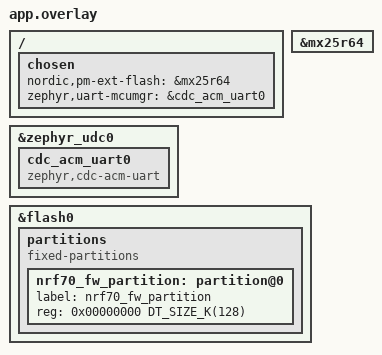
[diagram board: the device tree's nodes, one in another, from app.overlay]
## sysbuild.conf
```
# Add MCUboot
SB_CONFIG_BOOTLOADER_MCUBOOT=y

#Wifi stuff
SB_CONFIG_WIFI_NRF70=y

SB_CONFIG_MCUBOOT_UPDATEABLE_IMAGES=3

SB_CONFIG_WIFI_PATCHES_EXT_FLASH_STORE=y

SB_CONFIG_BOOTLOADER_MCUBOOT=y
SB_CONFIG_BOOT_SIGNATURE_TYPE_ECDSA_P256=y
SB_CONFIG_MCUBOOT_MODE_OVERWRITE_ONLY=y
SB_CONFIG_PM_EXTERNAL_FLASH_MCUBOOT_SECONDARY=y
SB_CONFIG_NETCORE_HCI_IPC=y
SB_CONFIG_NETCORE_APP_UPDATE=y
SB_CONFIG_SECURE_BOOT_NETCORE=y
```

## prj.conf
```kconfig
#
# Copyright (c) 2022 Nordic Semiconductor ASA
#
# SPDX-License-Identifier: LicenseRef-Nordic-5-Clause
#
# Enable MCUmgr and dependencies.

CONFIG_GPIO=y

# Enable mcumgr DFU in application
CONFIG_MCUMGR=y

# Enable MCUMGR management for both OS and Images
CONFIG_MCUMGR_GRP_OS=y
CONFIG_MCUMGR_GRP_IMG=y

# Configure MCUMGR transport to UART
CONFIG_MCUMGR_TRANSPORT_UART=y


# Configure dependencies for CONFIG_MCUMGR_GRP_IMG  
CONFIG_FLASH=y
CONFIG_IMG_MANAGER=y

# Configure dependencies for CONFIG_IMG_MANAGER  
CONFIG_STREAM_FLASH=y
CONFIG_FLASH_MAP=y

# Configure dependencies for CONFIG_MCUMGR_TRANSPORT_UART 
CONFIG_BASE64=y

# Step 5.3 - Enable USB subsystem
CONFIG_USB_DEVICE_STACK=y
CONFIG_UART_LINE_CTRL=y
CONFIG_USB_DEVICE_INITIALIZE_AT_BOOT=n

CONFIG_NET_BUF=y
CONFIG_ZCBOR=y
CONFIG_CRC=y
CONFIG_MCUMGR=y
CONFIG_STREAM_FLASH=y
CONFIG_FLASH_MAP=y

# Some command handlers require a large stack.
CONFIG_SYSTEM_WORKQUEUE_STACK_SIZE=2304
CONFIG_MAIN_STACK_SIZE=2048

# Ensure an MCUboot-compatible binary is generated.
CONFIG_BOOTLOADER_MCUBOOT=y

# Required by the `taskstat` command.
CONFIG_THREAD_MONITOR=y

# Support for taskstat command
CONFIG_MCUMGR_GRP_OS_TASKSTAT=y

# Enable statistics and statistic names.
CONFIG_STATS=y
CONFIG_STATS_NAMES=y

# Enable most core commands.
CONFIG_FLASH=y
CONFIG_IMG_MANAGER=y
CONFIG_MCUMGR_GRP_IMG=y
CONFIG_MCUMGR_GRP_OS=y
CONFIG_MCUMGR_GRP_STAT=y

# Enable logging
CONFIG_LOG=y
CONFIG_MCUBOOT_UTIL_LOG_LEVEL_WRN=y

# Disable debug logging
CONFIG_LOG_MAX_LEVEL=3

# Enable the Shell mcumgr transport.
CONFIG_BASE64=y
CONFIG_SHELL=y
CONFIG_SHELL_BACKEND_SERIAL=y
CONFIG_MCUMGR_TRANSPORT_SHELL=y
CONFIG_MCUMGR_TRANSPORT_SHELL_RX_BUF_COUNT=8

# Enable the storage erase command.
CONFIG_MCUMGR_GRP_ZBASIC=y
CONFIG_MCUMGR_GRP_ZBASIC_STORAGE_ERASE=y

# Init changes for QSPI XIP code placement
CONFIG_FLASH_INIT_PRIORITY=40
CONFIG_SHELL_BACKEND_SERIAL_INIT_PRIORITY=50

CONFIG_WIFI=y
CONFIG_WIFI_NM_WPA_SUPPLICANT=y
CONFIG_NRF_WIFI_PATCHES_EXT_FLASH_XIP=y
CONFIG_DFU_MULTI_IMAGE_MAX_IMAGE_COUNT=3

CONFIG_WIFI_CREDENTIALS=y
CONFIG_WIFI_CREDENTIALS_STATIC=y
CONFIG_WIFI_CREDENTIALS_STATIC_SSID="OpenWrt"
CONFIG_WIFI_CREDENTIALS_STATIC_PASSWORD="BillionIoT123"
#CONFIG_WIFI_CREDENTIALS_STATIC_SSID="<your_network_SSID>"
#CONFIG_WIFI_CREDENTIALS_STATIC_PASSWORD="<your_network_password>"


CONFIG_NET_MGMT=y
CONFIG_NET_MGMT_EVENT=y
CONFIG_NET_MGMT_EVENT_INFO=y
CONFIG_NET_MGMT_EVENT_STACK_SIZE=4096
CONFIG_NET_CONNECTION_MANAGER=y
CONFIG_WIFI_MGMT_EXT=y
CONFIG_DK_LIBRARY=y

# Logging
CONFIG_LOG=y

# System settings
CONFIG_NEWLIB_LIBC=y
CONFIG_NEWLIB_LIBC_NANO=n

# Networking
CONFIG_NETWORKING=y
CONFIG_NET_NATIVE=y
CONFIG_NET_SOCKETS=y
CONFIG_NET_L2_ETHERNET=y
CONFIG_NET_IPV6=n
CONFIG_NET_IPV4=y
CONFIG_NET_DHCPV4=y

# Memory
CONFIG_SYSTEM_WORKQUEUE_STACK_SIZE=4096
CONFIG_MAIN_STACK_SIZE=5200
CONFIG_HEAP_MEM_POOL_SIZE=153600
```

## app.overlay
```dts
/* Add external flash */
&mx25r64 {
	status = "okay";
};

/ {
	chosen {
		nordic,pm-ext-flash = &mx25r64;
	};
};


/* Step 5.1 - choose CDC ACM for mcumgr */
/ {
	chosen {
		zephyr,uart-mcumgr = &cdc_acm_uart0;
	};
};

/* Step 5.2 - Configure CDC ACM */
&zephyr_udc0 {
	cdc_acm_uart0: cdc_acm_uart0 {
		compatible = "zephyr,cdc-acm-uart";
	};
};


/ {
	chosen {
		nordic,pm-ext-flash = &mx25r64;
	};
};

&flash0 {
    partitions {
        compatible = "fixed-partitions";
        #address-cells = <1>;
        #size-cells = <1>;
        nrf70_fw_partition: partition@0 {
            label = "nrf70_fw_partition";
            reg = <0x00000000 DT_SIZE_K(128)>;
        };
    };
};
```

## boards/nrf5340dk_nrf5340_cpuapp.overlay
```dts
/ {
	chosen {
		zephyr,code-partition = &boot_partition;
		nordic,pm-ext-flash = &mx25r64;
	};
};


&flash0 {
    partitions {
        compatible = "fixed-partitions";
        #address-cells = <1>;
        #size-cells = <1>;
        nrf70_fw_partition: partition@0 {
            label = "nrf70_fw_partition";
            reg = <0x00000000 DT_SIZE_K(128)>;
        };
    };
};
```

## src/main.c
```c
/*
 * Copyright (c) 2016 Intel Corporation
 *
 * SPDX-License-Identifier: Apache-2.0
 */

#include <zephyr/kernel.h>
#include <zephyr/drivers/gpio.h>

/* Step 5.4 - Include header for usb */
#include <zephyr/usb/usb_device.h>

#include <zephyr/kernel.h>
#include <stdio.h>
#include <stdlib.h>

#include <zephyr/net/wifi.h>
#include <zephyr/net/wifi_mgmt.h>
#include <zephyr/net/net_mgmt.h>
#include <net/wifi_mgmt_ext.h>

#define SLEEP_TIME_MS   1000

/* The devicetree node identifier for the "led0" alias. */
#define LED0_NODE DT_ALIAS(led0)

#define WIFI_MGMT_EVENTS (NET_EVENT_WIFI_CONNECT_RESULT |		\
				NET_EVENT_WIFI_DISCONNECT_RESULT)

static struct net_mgmt_event_callback wifi_mgmt_cb;

static bool connected;
static K_SEM_DEFINE(run_wifi, 0, 1);

static const struct gpio_dt_spec led = GPIO_DT_SPEC_GET(LED0_NODE, gpios);

static void wifi_mgmt_event_handler(struct net_mgmt_event_callback *cb,
			  uint32_t mgmt_event, struct net_if *iface)
{
	switch (mgmt_event) {
	case NET_EVENT_WIFI_CONNECT_RESULT:
		LOG_INF("Network connected");
		connected = true;
		k_sem_give(&run_wifi);
		break;
	case NET_EVENT_WIFI_DISCONNECT_RESULT:
		if (connected == false) {
			LOG_INF("Waiting for network to be connected");
		} else {
			LOG_INF("Network disconnected");
			connected = false;
		}
		k_sem_reset(&run_wifi);
		break;
	default:
		break;
	}
}

static int wifi_args_to_params(struct wifi_connect_req_params *params)
{
	params->ssid = CONFIG_WIFI_CREDENTIALS_STATIC_SSID;
	params->ssid_length = strlen(params->ssid);

	params->psk = CONFIG_WIFI_CREDENTIALS_STATIC_PASSWORD;
	params->psk_length = strlen(params->psk);

	params->channel = WIFI_CHANNEL_ANY;
	params->security = WIFI_SECURITY_TYPE_PSK;
	params->mfp = WIFI_MFP_OPTIONAL;
	params->timeout = SYS_FOREVER_MS;
	params->band = WIFI_FREQ_BAND_UNKNOWN;
	memset(params->bssid, 0, sizeof(params->bssid));
	return 0;
}


int main(void)
{
	int ret;

	struct wifi_connect_req_params cnx_params;

	struct net_if *iface = net_if_get_first_wifi();
	if (iface == NULL) {
		LOG_ERR("Returned network interface is NULL");
		return -1;
	}

	/* Sleep to allow initialization of Wi-Fi driver */
	k_sleep(K_SECONDS(1));

	net_mgmt_init_event_callback(&wifi_mgmt_cb, wifi_mgmt_event_handler, WIFI_MGMT_EVENTS);
	net_mgmt_add_event_callback(&wifi_mgmt_cb);

	wifi_args_to_params(&cnx_params);

	LOG_INF("Connecting to Wi-Fi");
	int err = net_mgmt(NET_REQUEST_WIFI_CONNECT, iface, &cnx_params, sizeof(struct wifi_connect_req_params));
	if (err) {
		LOG_ERR("Connecting to Wi-Fi failed, err: %d", err);
		return ENOEXEC;
	}

	k_sem_take(&run_wifi, K_FOREVER);

	ret = usb_enable(NULL);
	if (ret) {
	return 0;
	}
	if (!device_is_ready(led.port)) {
		return 0;
	}

	ret = gpio_pin_configure_dt(&led, GPIO_OUTPUT_ACTIVE);
	if (ret < 0) {
		return 0;
	}

	while (1) {
		ret = gpio_pin_toggle_dt(&led);
		if (ret < 0) {
			return 0;
		}
		k_msleep(SLEEP_TIME_MS);
	}
	return 1;
}
```
